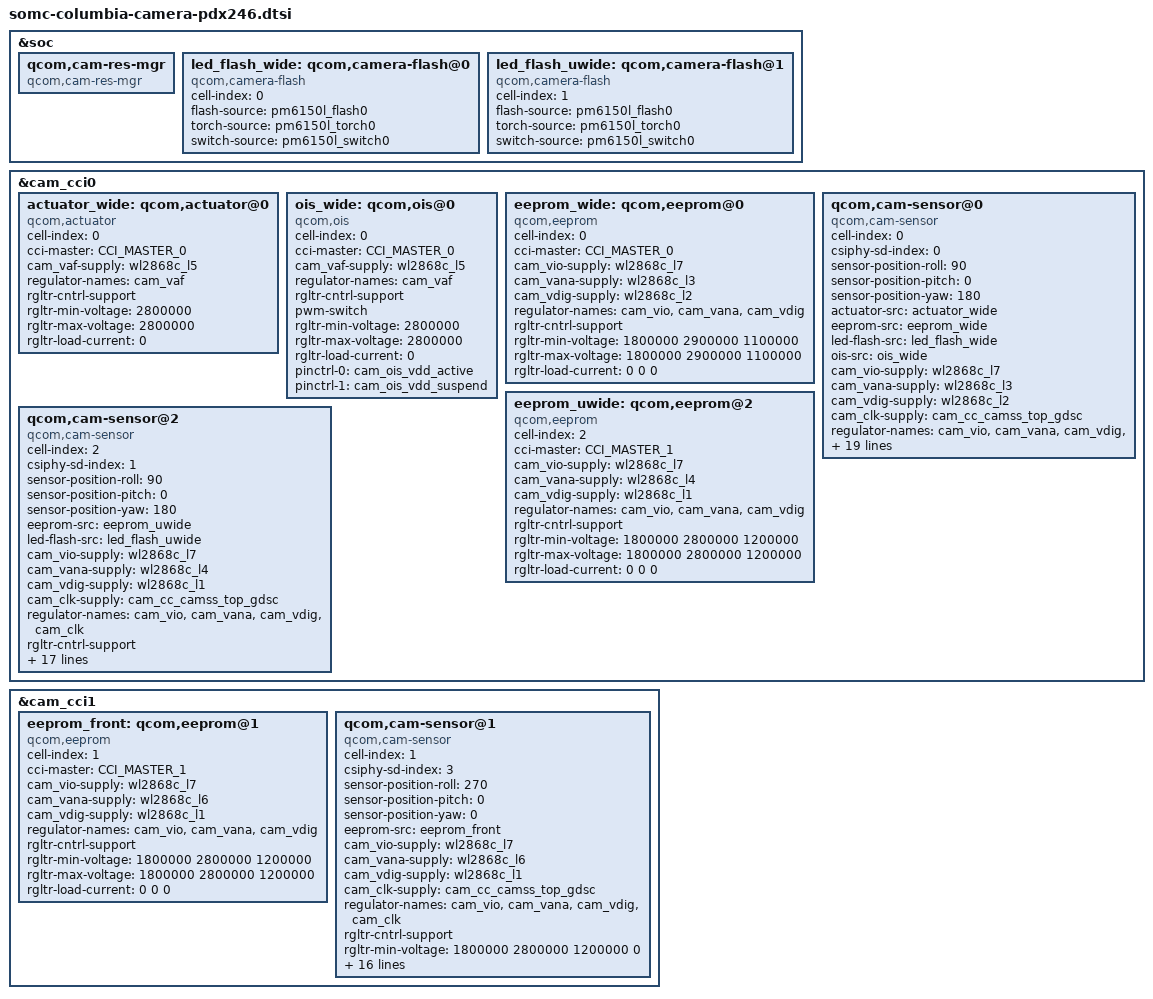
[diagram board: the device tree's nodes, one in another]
#include <dt-bindings/clock/qcom,camcc-parrot.h>
#include <dt-bindings/msm/msm-camera.h>

&soc {
	qcom,cam-res-mgr {
		compatible = "qcom,cam-res-mgr";
		status = "ok";
	};

	led_flash_wide: qcom,camera-flash@0 {
		cell-index = <0>;
		compatible = "qcom,camera-flash";
		flash-source = <&pm6150l_flash0>;
		torch-source = <&pm6150l_torch0>;
		switch-source = <&pm6150l_switch0>;
		status = "ok";
	};

	led_flash_uwide: qcom,camera-flash@1 {
		cell-index = <1>;
		compatible = "qcom,camera-flash";
		flash-source = <&pm6150l_flash0>;
		torch-source = <&pm6150l_torch0>;
		switch-source = <&pm6150l_switch0>;
		status = "ok";
	};
};

&cam_cci0 {
	// wide camera
	actuator_wide: qcom,actuator@0 {
		cell-index = <0>;
		compatible = "qcom,actuator";
		cci-master = <CCI_MASTER_0>;
		cam_vaf-supply = <&wl2868c_l5>;
		regulator-names = "cam_vaf";
		rgltr-cntrl-support;
		rgltr-min-voltage = <2800000>;
		rgltr-max-voltage = <2800000>;
		rgltr-load-current = <0>;
		status = "ok";
	};

	ois_wide: qcom,ois@0 {
		cell-index = <0>;
		compatible = "qcom,ois";
		cci-master = <CCI_MASTER_0>;
		cam_vaf-supply = <&wl2868c_l5>;
		regulator-names = "cam_vaf";
		rgltr-cntrl-support;
		pwm-switch;
		rgltr-min-voltage = <2800000>;
		rgltr-max-voltage = <2800000>;
		rgltr-load-current = <0>;
		pinctrl-names = "cam_default", "cam_suspend";
		pinctrl-0 = <&cam_ois_vdd_active>;
		pinctrl-1 = <&cam_ois_vdd_suspend>;
		status = "ok";
	};

	eeprom_wide: qcom,eeprom@0 {
		cell-index = <0>;
		compatible = "qcom,eeprom";
		cci-master = <CCI_MASTER_0>;
		cam_vio-supply = <&wl2868c_l7>;
		cam_vana-supply = <&wl2868c_l3>;
		cam_vdig-supply = <&wl2868c_l2>;
		regulator-names = "cam_vio", "cam_vana", "cam_vdig";
		rgltr-cntrl-support;
		rgltr-min-voltage = <1800000 2900000 1100000>;
		rgltr-max-voltage = <1800000 2900000 1100000>;
		rgltr-load-current = <0 0 0>;
		status = "ok";
	};

	qcom,cam-sensor@0 {
		cell-index = <0>;
		compatible = "qcom,cam-sensor";
		csiphy-sd-index = <0>;
		sensor-position-roll = <90>;
		sensor-position-pitch = <0>;
		sensor-position-yaw = <180>;
		actuator-src = <&actuator_wide>;
		eeprom-src = <&eeprom_wide>;
		led-flash-src = <&led_flash_wide>;
		ois-src = <&ois_wide>;
		cam_vio-supply = <&wl2868c_l7>;
		cam_vana-supply = <&wl2868c_l3>;
		cam_vdig-supply = <&wl2868c_l2>;
		cam_clk-supply = <&cam_cc_camss_top_gdsc>;
		regulator-names = "cam_vio", "cam_vana", "cam_vdig", "cam_clk";
		rgltr-cntrl-support;
		rgltr-min-voltage = <1800000 2900000 1100000 0>;
		rgltr-max-voltage = <1800000 2900000 1100000 0>;
		rgltr-load-current = <0 0 0 0>;
		gpio-no-mux = <0>;
		pinctrl-names = "cam_default", "cam_suspend";
		pinctrl-0 = <&cam_sensor_mclk0_active &cam_sensor_active_rst0>;
		pinctrl-1 = <&cam_sensor_mclk0_suspend &cam_sensor_suspend_rst0>;
		gpios = <&tlmm 39 0>,
			<&tlmm 44 0>;
		gpio-reset = <1>;
		gpio-req-tbl-num = <0 1>;
		gpio-req-tbl-flags = <1 0>;
		gpio-req-tbl-label = "CAMIF_MCLK0", "CAM_RESET0";
		cci-master = <CCI_MASTER_0>;
		clocks = <&camcc CAM_CC_MCLK0_CLK>;
		clock-names = "cam_clk";
		clock-cntl-level = "nominal";
		clock-rates = <24000000>;
		status = "ok";
	};

	// uwide camera
	eeprom_uwide: qcom,eeprom@2 {
		cell-index = <2>;
		compatible = "qcom,eeprom";
		cci-master = <CCI_MASTER_1>;
		cam_vio-supply = <&wl2868c_l7>;
		cam_vana-supply = <&wl2868c_l4>;
		cam_vdig-supply = <&wl2868c_l1>;
		regulator-names = "cam_vio", "cam_vana", "cam_vdig";
		rgltr-cntrl-support;
		rgltr-min-voltage = <1800000 2800000 1200000>;
		rgltr-max-voltage = <1800000 2800000 1200000>;
		rgltr-load-current = <0 0 0>;
		status = "ok";
	};

	qcom,cam-sensor@2 {
		cell-index = <2>;
		compatible = "qcom,cam-sensor";
		csiphy-sd-index = <1>;
		sensor-position-roll = <90>;
		sensor-position-pitch = <0>;
		sensor-position-yaw = <180>;
		eeprom-src = <&eeprom_uwide>;
		led-flash-src = <&led_flash_uwide>;
		cam_vio-supply = <&wl2868c_l7>;
		cam_vana-supply = <&wl2868c_l4>;
		cam_vdig-supply = <&wl2868c_l1>;
		cam_clk-supply = <&cam_cc_camss_top_gdsc>;
		regulator-names = "cam_vio", "cam_vana", "cam_vdig", "cam_clk";
		rgltr-cntrl-support;
		rgltr-min-voltage = <1800000 2800000 1200000 0>;
		rgltr-max-voltage = <1800000 2800000 1200000 0>;
		rgltr-load-current = <0 0 0 0>;
		gpio-no-mux = <0>;
		pinctrl-names = "cam_default", "cam_suspend";
		pinctrl-0 = <&cam_sensor_mclk1_active &cam_sensor_active_rst1>;
		pinctrl-1 = <&cam_sensor_mclk1_suspend &cam_sensor_suspend_rst1>;
		gpios = <&tlmm 40 0>,
			<&tlmm 45 0>;
		gpio-reset = <1>;
		gpio-req-tbl-num = <0 1>;
		gpio-req-tbl-flags = <1 0>;
		gpio-req-tbl-label = "CAMIF_MCLK1", "CAM_RESET1";
		cci-master = <CCI_MASTER_1>;
		clocks = <&camcc CAM_CC_MCLK1_CLK>;
		clock-names = "cam_clk";
		clock-cntl-level = "nominal";
		clock-rates = <24000000>;
		status = "ok";
	};
};

&cam_cci1 {
	// front camera
	eeprom_front: qcom,eeprom@1 {
		cell-index = <1>;
		compatible = "qcom,eeprom";
		cci-master = <CCI_MASTER_1>;
		cam_vio-supply = <&wl2868c_l7>;
		cam_vana-supply = <&wl2868c_l6>;
		cam_vdig-supply = <&wl2868c_l1>;
		regulator-names = "cam_vio", "cam_vana", "cam_vdig";
		rgltr-cntrl-support;
		rgltr-min-voltage = <1800000 2800000 1200000>;
		rgltr-max-voltage = <1800000 2800000 1200000>;
		rgltr-load-current = <0 0 0>;
		status = "ok";
	};

	qcom,cam-sensor@1 {
		cell-index = <1>;
		compatible = "qcom,cam-sensor";
		csiphy-sd-index = <3>;
		sensor-position-roll = <270>;
		sensor-position-pitch = <0>;
		sensor-position-yaw = <0>;
		eeprom-src = <&eeprom_front>;
		cam_vio-supply = <&wl2868c_l7>;
		cam_vana-supply = <&wl2868c_l6>;
		cam_vdig-supply = <&wl2868c_l1>;
		cam_clk-supply = <&cam_cc_camss_top_gdsc>;
		regulator-names = "cam_vio", "cam_vana", "cam_vdig", "cam_clk";
		rgltr-cntrl-support;
		rgltr-min-voltage = <1800000 2800000 1200000 0>;
		rgltr-max-voltage = <1800000 2800000 1200000 0>;
		rgltr-load-current = <0 0 0 0>;
		gpio-no-mux = <0>;
		pinctrl-names = "cam_default", "cam_suspend";
		pinctrl-0 = <&cam_sensor_mclk3_active &cam_sensor_active_rst3>;
		pinctrl-1 = <&cam_sensor_mclk3_suspend &cam_sensor_suspend_rst3>;
		gpios = <&tlmm 42 0>,
			<&tlmm 47 0>;
		gpio-reset = <1>;
		gpio-req-tbl-num = <0 1>;
		gpio-req-tbl-flags = <1 0>;
		gpio-req-tbl-label = "CAMIF_MCLK3", "CAM_RESET3";
		cci-master = <CCI_MASTER_1>;
		clocks = <&camcc CAM_CC_MCLK3_CLK>;
		clock-names = "cam_clk";
		clock-cntl-level = "nominal";
		clock-rates = <24000000>;
		status = "ok";
	};
};
